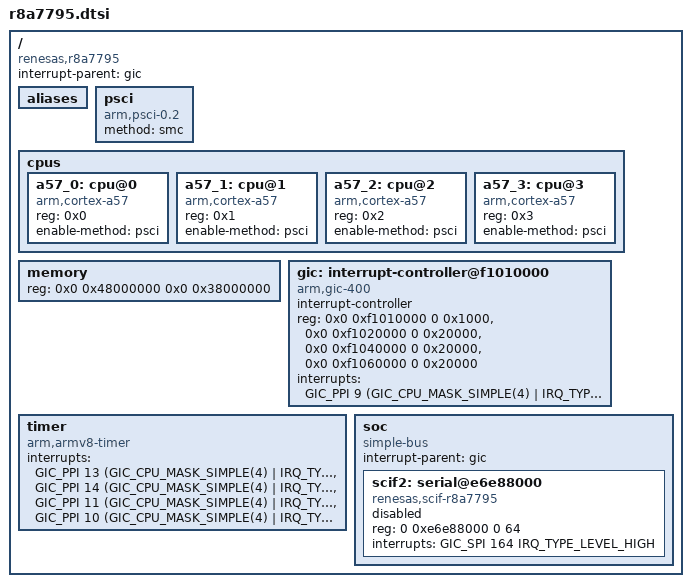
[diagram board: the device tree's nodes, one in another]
/*
 * Device Tree Source for the r8a7795 SoC
 *
 * Copyright (C) 2018 Anup Patel.
 * Copyright (C) 2015 Renesas Electronics Corp.
 *
 * This file is licensed under the terms of the GNU General Public License
 * version 2.  This program is licensed "as is" without any warranty of any
 * kind, whether express or implied.
 */

#include <dt-bindings/interrupt-controller/arm-gic.h>
#include <dt-bindings/interrupt-controller/irq.h>

/memreserve/ 0x54000000 0x04000000;

/ {
	compatible = "renesas,r8a7795";
	interrupt-parent = <&gic>;
	#address-cells = <2>;
	#size-cells = <2>;

	aliases {
	};

	psci {
		compatible = "arm,psci-0.2";
		method = "smc";
	};

	cpus {
		#address-cells = <1>;
		#size-cells = <0>;

		a57_0: cpu@0 {
			compatible = "arm,cortex-a57", "arm,armv8";
			reg = <0x0>;
			device_type = "cpu";
			enable-method = "psci";
		};

		a57_1: cpu@1 {
			compatible = "arm,cortex-a57","arm,armv8";
			reg = <0x1>;
			device_type = "cpu";
			enable-method = "psci";
		};

		a57_2: cpu@2 {
			compatible = "arm,cortex-a57","arm,armv8";
			reg = <0x2>;
			device_type = "cpu";
			enable-method = "psci";
		};

		a57_3: cpu@3 {
			compatible = "arm,cortex-a57","arm,armv8";
			reg = <0x3>;
			device_type = "cpu";
			enable-method = "psci";
		};

	};


        memory {
		device_type = "memory";
		/* first 128MB is reserved for secure area. */
		reg = <0x0 0x48000000 0x0 0x38000000>;
        };


	gic: interrupt-controller@f1010000 {
		compatible = "arm,gic-400", "arm,cortex-a15-gic";
		#interrupt-cells = <3>;
		#address-cells = <0>;
		interrupt-controller;
		reg = <0x0 0xf1010000 0 0x1000>,
		      <0x0 0xf1020000 0 0x20000>,
		      <0x0 0xf1040000 0 0x20000>,
		      <0x0 0xf1060000 0 0x20000>;
		interrupts = <GIC_PPI 9
				(GIC_CPU_MASK_SIMPLE(4) | IRQ_TYPE_LEVEL_HIGH)>;
	};


	timer {
		compatible = "arm,armv8-timer";
		interrupts = <GIC_PPI 13
				(GIC_CPU_MASK_SIMPLE(4) | IRQ_TYPE_LEVEL_LOW)>,
			     <GIC_PPI 14
				(GIC_CPU_MASK_SIMPLE(4) | IRQ_TYPE_LEVEL_LOW)>,
			     <GIC_PPI 11
				(GIC_CPU_MASK_SIMPLE(4) | IRQ_TYPE_LEVEL_LOW)>,
			     <GIC_PPI 10
				(GIC_CPU_MASK_SIMPLE(4) | IRQ_TYPE_LEVEL_LOW)>;
	};

	soc {
		compatible = "simple-bus";
		interrupt-parent = <&gic>;

		#address-cells = <2>;
		#size-cells = <2>;
		ranges;

		
		scif2: serial@e6e88000 {
			compatible = "renesas,scif-r8a7795",
				     "renesas,rcar-gen3-scif", "renesas,scif";
			reg = <0 0xe6e88000 0 64>;
			interrupts = <GIC_SPI 164 IRQ_TYPE_LEVEL_HIGH>;
			dma-names = "tx", "rx";
			status = "disabled";
		};

	};
};
